# nrf5340_application register map
Vendor: Nordic Semiconductor; Series: nrf53; File version: 1
CPU: CM33 r0p4, little endian, MPU, FPU, 3 interrupt priority bits, 69 interrupts
Registers are 32-bit, read-write, reset 0x0 unless marked. A register's access mark holds for its fields unless they carry their own. Offsets are from the block's base; [hi:lo] are bit positions; lines under a group give offsets from that group; {n}, {i} and the like mark numbered series; 'fields as' and 'values as' point back to an identical list.

## USBD_NS — Universal serial bus device 0
Base 0x40036000
Same registers: USBD_S 0x50036000
{0x4+4i} TASKS_STARTEPIN[{i}] (i=0..7) wo — Description collection: Captures the EPIN[n].PTR and EPIN[n].MAXCNT registers values, and enables endpoint IN n to respond to traffic from host
  [0] TASKS_STARTEPIN — Captures the EPIN[n].PTR and EPIN[n].MAXCNT registers values, and enables endpoint IN n to respond to traffic from host
    1=Trigger task
0x24 TASKS_STARTISOIN wo — Captures the ISOIN.PTR and ISOIN.MAXCNT registers values, and enables sending data on ISO endpoint
  [0] TASKS_STARTISOIN
    1=Trigger task
{0x28+4i} TASKS_STARTEPOUT[{i}] (i=0..7) wo — Description collection: Captures the EPOUT[n].PTR and EPOUT[n].MAXCNT registers values, and enables endpoint n to respond to traffic from host
  [0] TASKS_STARTEPOUT — Captures the EPOUT[n].PTR and EPOUT[n].MAXCNT registers values, and enables endpoint n to respond to traffic from host
    1=Trigger task
0x48 TASKS_STARTISOOUT wo — Captures the ISOOUT.PTR and ISOOUT.MAXCNT registers values, and enables receiving of data on ISO endpoint
  [0] TASKS_STARTISOOUT
    1=Trigger task
0x4C TASKS_EP0RCVOUT wo — Allows OUT data stage on control endpoint 0
  [0] TASKS_EP0RCVOUT
    1=Trigger task
0x50 TASKS_EP0STATUS wo — Allows status stage on control endpoint 0
  [0] TASKS_EP0STATUS
    1=Trigger task
0x54 TASKS_EP0STALL wo — Stalls data and status stage on control endpoint 0
  [0] TASKS_EP0STALL
    1=Trigger task
0x58 TASKS_DPDMDRIVE wo — Forces D+ and D- lines into the state defined in the DPDMVALUE register
  [0] TASKS_DPDMDRIVE
    1=Trigger task
0x5C TASKS_DPDMNODRIVE wo — Stops forcing D+ and D- lines into any state (USB engine takes control)
  [0] TASKS_DPDMNODRIVE
    1=Trigger task
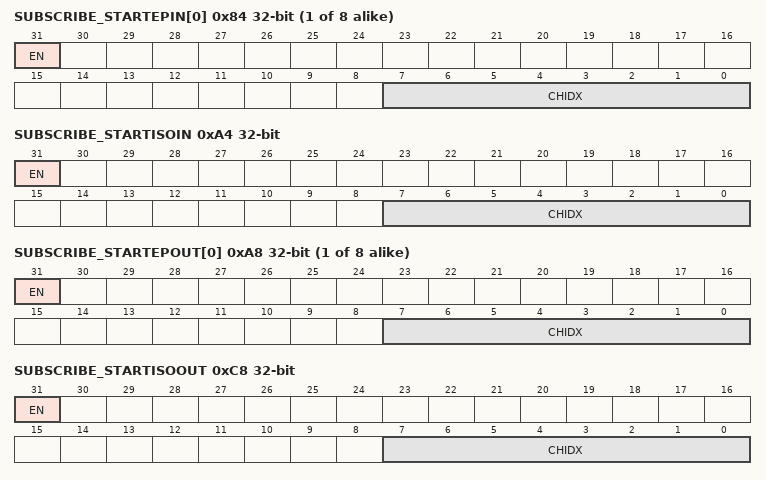
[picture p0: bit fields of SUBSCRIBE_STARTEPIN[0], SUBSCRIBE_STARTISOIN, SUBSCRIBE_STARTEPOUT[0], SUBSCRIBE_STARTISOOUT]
{0x84+4i} SUBSCRIBE_STARTEPIN[{i}] (i=0..7) — Description collection: Subscribe configuration for task STARTEPIN[n]
  [31] EN
    0=Disabled (Disable subscription); 1=Enabled (Enable subscription)
  [7:0] CHIDX — DPPI channel that task STARTEPIN[n] will subscribe to
0xA4 SUBSCRIBE_STARTISOIN — Subscribe configuration for task STARTISOIN
  [31] EN
    values as SUBSCRIBE_STARTEPIN[0].EN
  [7:0] CHIDX — DPPI channel that task STARTISOIN will subscribe to
{0xA8+4i} SUBSCRIBE_STARTEPOUT[{i}] (i=0..7) — Description collection: Subscribe configuration for task STARTEPOUT[n]
  [31] EN
    values as SUBSCRIBE_STARTEPIN[0].EN
  [7:0] CHIDX — DPPI channel that task STARTEPOUT[n] will subscribe to
0xC8 SUBSCRIBE_STARTISOOUT — Subscribe configuration for task STARTISOOUT
  [31] EN
    values as SUBSCRIBE_STARTEPIN[0].EN
  [7:0] CHIDX — DPPI channel that task STARTISOOUT will subscribe to
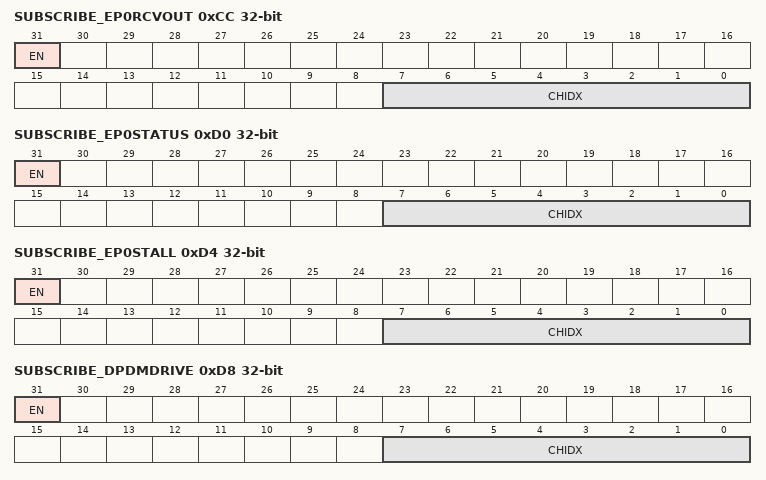
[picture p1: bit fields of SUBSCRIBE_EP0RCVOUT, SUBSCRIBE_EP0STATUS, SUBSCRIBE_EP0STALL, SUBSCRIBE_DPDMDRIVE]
0xCC SUBSCRIBE_EP0RCVOUT — Subscribe configuration for task EP0RCVOUT
  [31] EN
    values as SUBSCRIBE_STARTEPIN[0].EN
  [7:0] CHIDX — DPPI channel that task EP0RCVOUT will subscribe to
0xD0 SUBSCRIBE_EP0STATUS — Subscribe configuration for task EP0STATUS
  [31] EN
    values as SUBSCRIBE_STARTEPIN[0].EN
  [7:0] CHIDX — DPPI channel that task EP0STATUS will subscribe to
0xD4 SUBSCRIBE_EP0STALL — Subscribe configuration for task EP0STALL
  [31] EN
    values as SUBSCRIBE_STARTEPIN[0].EN
  [7:0] CHIDX — DPPI channel that task EP0STALL will subscribe to
0xD8 SUBSCRIBE_DPDMDRIVE — Subscribe configuration for task DPDMDRIVE
  [31] EN
    values as SUBSCRIBE_STARTEPIN[0].EN
  [7:0] CHIDX — DPPI channel that task DPDMDRIVE will subscribe to
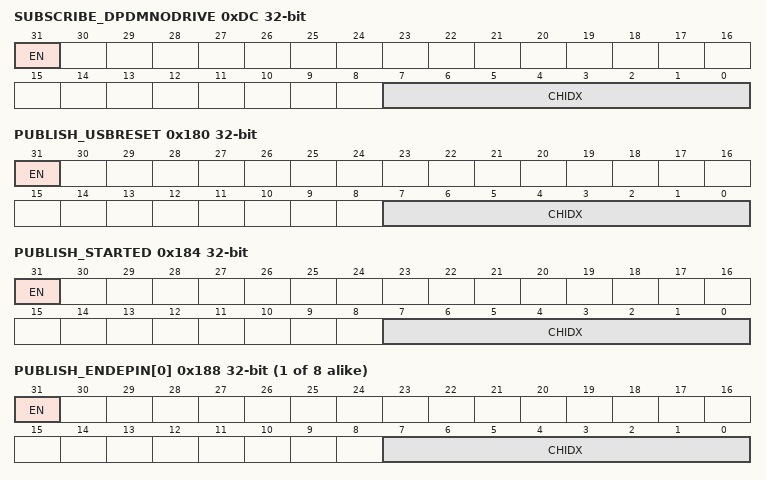
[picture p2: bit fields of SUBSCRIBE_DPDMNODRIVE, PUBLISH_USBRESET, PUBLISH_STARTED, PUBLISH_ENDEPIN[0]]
0xDC SUBSCRIBE_DPDMNODRIVE — Subscribe configuration for task DPDMNODRIVE
  [31] EN
    values as SUBSCRIBE_STARTEPIN[0].EN
  [7:0] CHIDX — DPPI channel that task DPDMNODRIVE will subscribe to
0x100 EVENTS_USBRESET — Signals that a USB reset condition has been detected on USB lines
  [0] EVENTS_USBRESET
    0=NotGenerated (Event not generated); 1=Generated (Event generated)
0x104 EVENTS_STARTED — Confirms that the EPIN[n].PTR and EPIN[n].MAXCNT, or EPOUT[n].PTR and EPOUT[n].MAXCNT registers have been captured on all endpoints reported in the EPSTATUS register
  [0] EVENTS_STARTED
    values as EVENTS_USBRESET.EVENTS_USBRESET
{0x108+4i} EVENTS_ENDEPIN[{i}] (i=0..7) — Description collection: The whole EPIN[n] buffer has been consumed. The buffer can be accessed safely by software.
  [0] EVENTS_ENDEPIN — The whole EPIN[n] buffer has been consumed. The buffer can be accessed safely by software.
    values as EVENTS_USBRESET.EVENTS_USBRESET
0x128 EVENTS_EP0DATADONE — An acknowledged data transfer has taken place on the control endpoint
  [0] EVENTS_EP0DATADONE
    values as EVENTS_USBRESET.EVENTS_USBRESET
0x12C EVENTS_ENDISOIN — The whole ISOIN buffer has been consumed. The buffer can be accessed safely by software.
  [0] EVENTS_ENDISOIN
    values as EVENTS_USBRESET.EVENTS_USBRESET
{0x130+4i} EVENTS_ENDEPOUT[{i}] (i=0..7) — Description collection: The whole EPOUT[n] buffer has been consumed. The buffer can be accessed safely by software.
  [0] EVENTS_ENDEPOUT — The whole EPOUT[n] buffer has been consumed. The buffer can be accessed safely by software.
    values as EVENTS_USBRESET.EVENTS_USBRESET
0x150 EVENTS_ENDISOOUT — The whole ISOOUT buffer has been consumed. The buffer can be accessed safely by software.
  [0] EVENTS_ENDISOOUT
    values as EVENTS_USBRESET.EVENTS_USBRESET
0x154 EVENTS_SOF — Signals that a SOF (start of frame) condition has been detected on USB lines
  [0] EVENTS_SOF
    values as EVENTS_USBRESET.EVENTS_USBRESET
0x158 EVENTS_USBEVENT — An event or an error not covered by specific events has occurred. Check EVENTCAUSE register to find the cause.
  [0] EVENTS_USBEVENT
    values as EVENTS_USBRESET.EVENTS_USBRESET
0x15C EVENTS_EP0SETUP — A valid SETUP token has been received (and acknowledged) on the control endpoint
  [0] EVENTS_EP0SETUP
    values as EVENTS_USBRESET.EVENTS_USBRESET
0x160 EVENTS_EPDATA — A data transfer has occurred on a data endpoint, indicated by the EPDATASTATUS register
  [0] EVENTS_EPDATA
    values as EVENTS_USBRESET.EVENTS_USBRESET
0x180 PUBLISH_USBRESET — Publish configuration for event USBRESET
  [31] EN
    0=Disabled (Disable publishing); 1=Enabled (Enable publishing)
  [7:0] CHIDX — DPPI channel that event USBRESET will publish to.
0x184 PUBLISH_STARTED — Publish configuration for event STARTED
  [31] EN
    values as PUBLISH_USBRESET.EN
  [7:0] CHIDX — DPPI channel that event STARTED will publish to.
{0x188+4i} PUBLISH_ENDEPIN[{i}] (i=0..7) — Description collection: Publish configuration for event ENDEPIN[n]
  [31] EN
    values as PUBLISH_USBRESET.EN
  [7:0] CHIDX — DPPI channel that event ENDEPIN[n] will publish to.
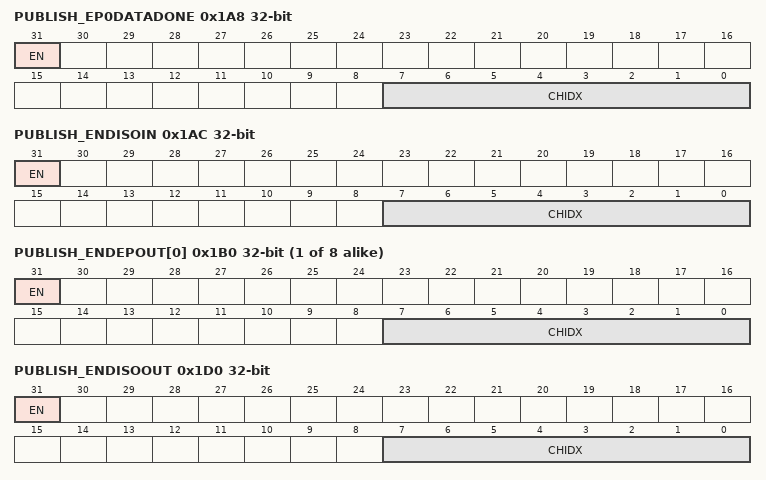
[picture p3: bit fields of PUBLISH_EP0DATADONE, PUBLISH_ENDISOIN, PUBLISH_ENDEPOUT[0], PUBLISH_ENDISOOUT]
0x1A8 PUBLISH_EP0DATADONE — Publish configuration for event EP0DATADONE
  [31] EN
    values as PUBLISH_USBRESET.EN
  [7:0] CHIDX — DPPI channel that event EP0DATADONE will publish to.
0x1AC PUBLISH_ENDISOIN — Publish configuration for event ENDISOIN
  [31] EN
    values as PUBLISH_USBRESET.EN
  [7:0] CHIDX — DPPI channel that event ENDISOIN will publish to.
{0x1B0+4i} PUBLISH_ENDEPOUT[{i}] (i=0..7) — Description collection: Publish configuration for event ENDEPOUT[n]
  [31] EN
    values as PUBLISH_USBRESET.EN
  [7:0] CHIDX — DPPI channel that event ENDEPOUT[n] will publish to.
0x1D0 PUBLISH_ENDISOOUT — Publish configuration for event ENDISOOUT
  [31] EN
    values as PUBLISH_USBRESET.EN
  [7:0] CHIDX — DPPI channel that event ENDISOOUT will publish to.
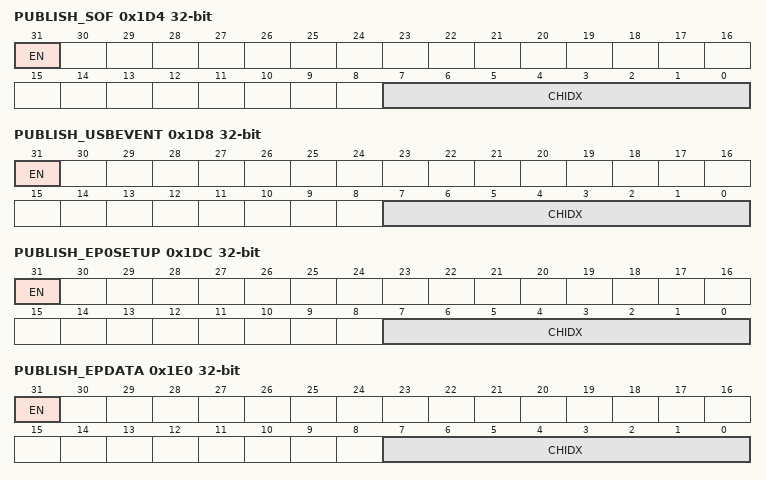
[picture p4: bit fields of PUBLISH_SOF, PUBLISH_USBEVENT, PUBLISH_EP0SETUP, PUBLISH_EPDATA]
0x1D4 PUBLISH_SOF — Publish configuration for event SOF
  [31] EN
    values as PUBLISH_USBRESET.EN
  [7:0] CHIDX — DPPI channel that event SOF will publish to.
0x1D8 PUBLISH_USBEVENT — Publish configuration for event USBEVENT
  [31] EN
    values as PUBLISH_USBRESET.EN
  [7:0] CHIDX — DPPI channel that event USBEVENT will publish to.
0x1DC PUBLISH_EP0SETUP — Publish configuration for event EP0SETUP
  [31] EN
    values as PUBLISH_USBRESET.EN
  [7:0] CHIDX — DPPI channel that event EP0SETUP will publish to.
0x1E0 PUBLISH_EPDATA — Publish configuration for event EPDATA
  [31] EN
    values as PUBLISH_USBRESET.EN
  [7:0] CHIDX — DPPI channel that event EPDATA will publish to.
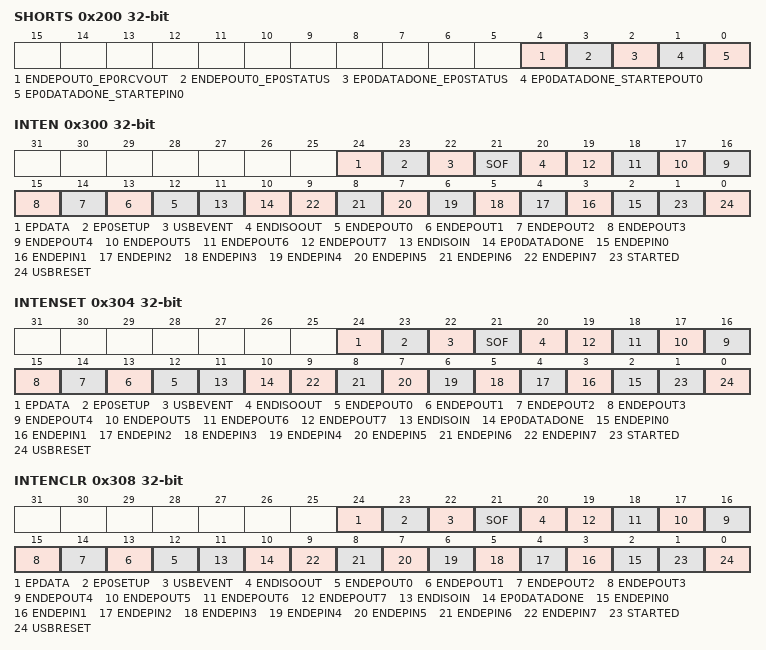
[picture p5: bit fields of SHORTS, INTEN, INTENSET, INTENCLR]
0x200 SHORTS — Shortcuts between local events and tasks
  [all] fields
    0=Disabled (Disable shortcut); 1=Enabled (Enable shortcut)
  [4] ENDEPOUT0_EP0RCVOUT — Shortcut between event ENDEPOUT[0] and task EP0RCVOUT
  [3] ENDEPOUT0_EP0STATUS — Shortcut between event ENDEPOUT[0] and task EP0STATUS
  [2] EP0DATADONE_EP0STATUS — Shortcut between event EP0DATADONE and task EP0STATUS
  [1] EP0DATADONE_STARTEPOUT0 — Shortcut between event EP0DATADONE and task STARTEPOUT[0]
  [0] EP0DATADONE_STARTEPIN0 — Shortcut between event EP0DATADONE and task STARTEPIN[0]
0x300 INTEN — Enable or disable interrupt
  [all] fields
    0=Disabled; 1=Enabled
  [24] EPDATA — Enable or disable interrupt for event EPDATA
  [23] EP0SETUP — Enable or disable interrupt for event EP0SETUP
  [22] USBEVENT — Enable or disable interrupt for event USBEVENT
  [21] SOF — Enable or disable interrupt for event SOF
  [20] ENDISOOUT — Enable or disable interrupt for event ENDISOOUT
  [n+12] ENDEPOUT{n} (n=0..7) — Enable or disable interrupt for event ENDEPOUT[{n}]
  [11] ENDISOIN — Enable or disable interrupt for event ENDISOIN
  [10] EP0DATADONE — Enable or disable interrupt for event EP0DATADONE
  [n+2] ENDEPIN{n} (n=0..7) — Enable or disable interrupt for event ENDEPIN[{n}]
  [1] STARTED — Enable or disable interrupt for event STARTED
  [0] USBRESET — Enable or disable interrupt for event USBRESET
0x304 INTENSET — Enable interrupt
  [all] fields
    on read: 0=Disabled (Read: Disabled); 1=Enabled (Read: Enabled) | on write: 1=Set (Enable)
  [24] EPDATA — Write '1' to enable interrupt for event EPDATA
  [23] EP0SETUP — Write '1' to enable interrupt for event EP0SETUP
  [22] USBEVENT — Write '1' to enable interrupt for event USBEVENT
  [21] SOF — Write '1' to enable interrupt for event SOF
  [20] ENDISOOUT — Write '1' to enable interrupt for event ENDISOOUT
  [n+12] ENDEPOUT{n} (n=0..7) — Write '1' to enable interrupt for event ENDEPOUT[{n}]
  [11] ENDISOIN — Write '1' to enable interrupt for event ENDISOIN
  [10] EP0DATADONE — Write '1' to enable interrupt for event EP0DATADONE
  [n+2] ENDEPIN{n} (n=0..7) — Write '1' to enable interrupt for event ENDEPIN[{n}]
  [1] STARTED — Write '1' to enable interrupt for event STARTED
  [0] USBRESET — Write '1' to enable interrupt for event USBRESET
0x308 INTENCLR — Disable interrupt
  [all] fields
    on read: 0=Disabled (Read: Disabled); 1=Enabled (Read: Enabled) | on write: 1=Clear (Disable)
  [24] EPDATA — Write '1' to disable interrupt for event EPDATA
  [23] EP0SETUP — Write '1' to disable interrupt for event EP0SETUP
  [22] USBEVENT — Write '1' to disable interrupt for event USBEVENT
  [21] SOF — Write '1' to disable interrupt for event SOF
  [20] ENDISOOUT — Write '1' to disable interrupt for event ENDISOOUT
  [n+12] ENDEPOUT{n} (n=0..7) — Write '1' to disable interrupt for event ENDEPOUT[{n}]
  [11] ENDISOIN — Write '1' to disable interrupt for event ENDISOIN
  [10] EP0DATADONE — Write '1' to disable interrupt for event EP0DATADONE
  [n+2] ENDEPIN{n} (n=0..7) — Write '1' to disable interrupt for event ENDEPIN[{n}]
  [1] STARTED — Write '1' to disable interrupt for event STARTED
  [0] USBRESET — Write '1' to disable interrupt for event USBRESET
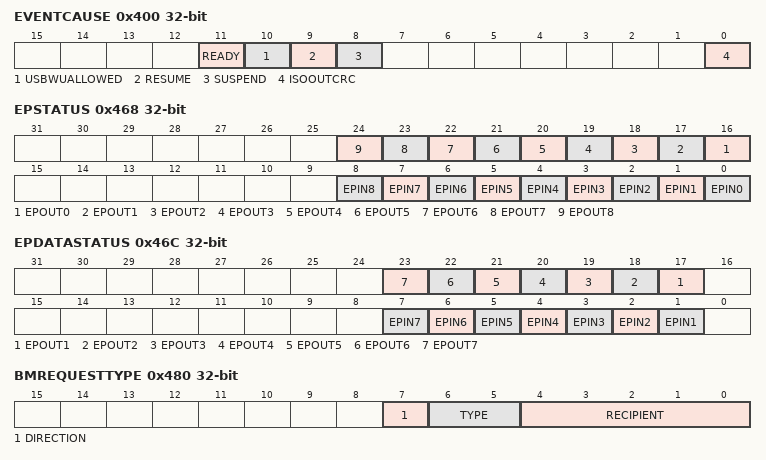
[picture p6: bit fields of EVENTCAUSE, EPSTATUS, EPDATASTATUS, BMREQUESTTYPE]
0x400 EVENTCAUSE write-1-clears — Details on what caused the USBEVENT event
  [11] READY — USB device is ready for normal operation. Write '1' to clear.
    0=NotDetected (USBEVENT was not issued due to USBD peripheral ready); 1=Ready (USBD peripheral is ready)
  [10] USBWUALLOWED — USB MAC has been woken up and operational. Write '1' to clear.
    0=NotAllowed (Wake up not allowed); 1=Allowed (Wake up allowed)
  [9] RESUME — Signals that a RESUME condition (K state or activity restart) has been detected on USB lines. Write '1' to clear.
    0=NotDetected (Resume not detected); 1=Detected (Resume detected)
  [8] SUSPEND — Signals that USB lines have been idle long enough for the device to enter suspend. Write '1' to clear.
    0=NotDetected (Suspend not detected); 1=Detected (Suspend detected)
  [0] ISOOUTCRC — CRC error was detected on isochronous OUT endpoint 8. Write '1' to clear.
    0=NotDetected (No error detected); 1=Detected (Error detected)
0x420 HALTED group — Unspecified
  {0x0+4j} EPIN[{j}] (j=0..7) ro — Description collection: IN endpoint halted status. Can be used as is as response to a GetStatus() request to endpoint.
    [15:0] GETSTATUS — IN endpoint halted status. Can be used as is as response to a GetStatus() request to endpoint.
      0=NotHalted (Endpoint is not halted); 1=Halted (Endpoint is halted)
  {0x24+4j} EPOUT[{j}] (j=0..7) ro — Description collection: OUT endpoint halted status. Can be used as is as response to a GetStatus() request to endpoint.
    [15:0] GETSTATUS — OUT endpoint halted status. Can be used as is as response to a GetStatus() request to endpoint.
      values as HALTED.EPIN[0].GETSTATUS
0x468 EPSTATUS write-1-clears — Provides information on which endpoint's EasyDMA registers have been captured
  [all] fields
    0=NoData (EasyDMA registers have not been captured for this endpoint); 1=DataDone (EasyDMA registers have been captured for this endpoint)
  [n+16] EPOUT{n} (n=0..8) — Captured state of endpoint's EasyDMA registers. Write '1' to clear.
  [n] EPIN{n} (n=0..8) — Captured state of endpoint's EasyDMA registers. Write '1' to clear.
0x46C EPDATASTATUS write-1-clears — Provides information on which endpoint(s) an acknowledged data transfer has occurred (EPDATA event)
  [n+16] EPOUT{n} (n=1..7) — Acknowledged data transfer on this OUT endpoint. Write '1' to clear.
    0=NotStarted (No acknowledged data transfer on this endpoint); 1=Started (Acknowledged data transfer on this endpoint has occurred)
  [n] EPIN{n} (n=1..7) — Acknowledged data transfer on this IN endpoint. Write '1' to clear.
    0=NotDone (No acknowledged data transfer on this endpoint); 1=DataDone (Acknowledged data transfer on this endpoint has occurred)
0x470 USBADDR ro — Device USB address
  [6:0] ADDR
0x480 BMREQUESTTYPE ro — SETUP data, byte 0, bmRequestType
  [7] DIRECTION — Data transfer direction
    0=HostToDevice; 1=DeviceToHost
  [6:5] TYPE — Data transfer type
    0=Standard; 1=Class; 2=Vendor
  [4:0] RECIPIENT — Data transfer type
    0=Device; 1=Interface; 2=Endpoint; 3=Other
0x484 BREQUEST ro — SETUP data, byte 1, bRequest
  [7:0] BREQUEST — SETUP data, byte 1, bRequest. Values provided for standard requests only, user must implement class and vendor values.
    0=STD_GET_STATUS (Standard request GET_STATUS); 1=STD_CLEAR_FEATURE (Standard request CLEAR_FEATURE); 3=STD_SET_FEATURE (Standard request SET_FEATURE); 5=STD_SET_ADDRESS (Standard request SET_ADDRESS); 6=STD_GET_DESCRIPTOR (Standard request GET_DESCRIPTOR); 7=STD_SET_DESCRIPTOR (Standard request SET_DESCRIPTOR); 8=STD_GET_CONFIGURATION (Standard request GET_CONFIGURATION); 9=STD_SET_CONFIGURATION (Standard request SET_CONFIGURATION); 10=STD_GET_INTERFACE (Standard request GET_INTERFACE); 11=STD_SET_INTERFACE (Standard request SET_INTERFACE); 12=STD_SYNCH_FRAME (Standard request SYNCH_FRAME)
0x488 WVALUEL ro — SETUP data, byte 2, LSB of wValue
  [7:0] WVALUEL
0x48C WVALUEH ro — SETUP data, byte 3, MSB of wValue
  [7:0] WVALUEH
0x490 WINDEXL ro — SETUP data, byte 4, LSB of wIndex
  [7:0] WINDEXL
0x494 WINDEXH ro — SETUP data, byte 5, MSB of wIndex
  [7:0] WINDEXH
0x498 WLENGTHL ro — SETUP data, byte 6, LSB of wLength
  [7:0] WLENGTHL
0x49C WLENGTHH ro — SETUP data, byte 7, MSB of wLength
  [7:0] WLENGTHH
0x4A0 SIZE group — Unspecified
  {0x0+4j} EPOUT[{j}] (j=0..7) write-0-clears — Description collection: Number of bytes received last in the data stage of this OUT endpoint
    [6:0] SIZE — Number of bytes received last in the data stage of this OUT endpoint
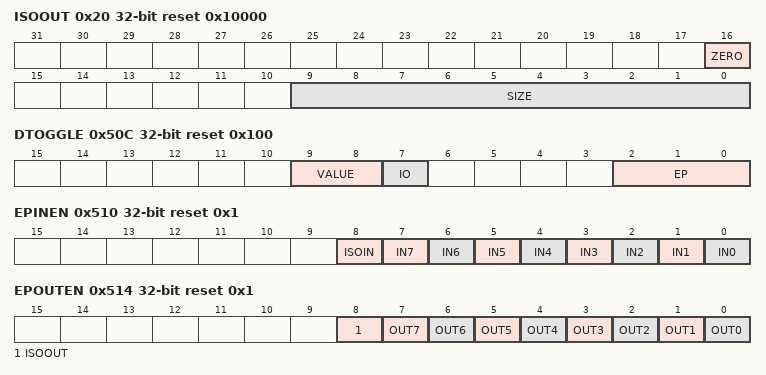
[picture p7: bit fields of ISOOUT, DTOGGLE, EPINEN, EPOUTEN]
  0x20 ISOOUT ro reset 0x10000 — Number of bytes received last on this ISO OUT data endpoint
    [16] ZERO — Zero-length data packet received
      0=Normal (No zero-length data received, use value in SIZE); 1=ZeroData (Zero-length data received, ignore value in SIZE)
    [9:0] SIZE — Number of bytes received last on this ISO OUT data endpoint
0x500 ENABLE — Enable USB
  [0] ENABLE
    0=Disabled (USB peripheral is disabled); 1=Enabled (USB peripheral is enabled)
0x504 USBPULLUP — Control of the USB pull-up
  [0] CONNECT — Control of the USB pull-up on the D+ line
    0=Disabled (Pull-up is disconnected); 1=Enabled (Pull-up is connected to D+)
0x508 DPDMVALUE — State D+ and D- lines will be forced into by the DPDMDRIVE task. The DPDMNODRIVE task reverts the control of the lines to MAC IP (no forcing).
  [4:0] STATE — State D+ and D- lines will be forced into by the DPDMDRIVE task
    1=Resume (D+ forced low, D- forced high (K state) for a timing preset in hardware (50 us or 5 ms, depending on bus state)); 2=J (D+ forced high, D- forced low (J state)); 4=K (D+ forced low, D- forced high (K state))
0x50C DTOGGLE reset 0x100 — Data toggle control and status
  [9:8] VALUE — Data toggle value
    0=Nop (No action on data toggle when writing the register with this value); 1=Data0 (Data toggle is DATA0 on endpoint set by EP and IO); 2=Data1 (Data toggle is DATA1 on endpoint set by EP and IO)
  [7] IO — Selects IN or OUT endpoint
    0=Out (Selects OUT endpoint); 1=In (Selects IN endpoint)
  [2:0] EP — Select bulk endpoint number
0x510 EPINEN reset 0x1 — Endpoint IN enable
  [8] ISOIN — Enable ISO IN endpoint
    0=Disable ISO IN endpoint 8; 1=Enable ISO IN endpoint 8
  [n] IN{n} (n=0..7) — Enable IN endpoint {n}
    0=Disable endpoint IN {n} (no response to IN tokens); 1=Enable endpoint IN {n} (response to IN tokens)
0x514 EPOUTEN reset 0x1 — Endpoint OUT enable
  [8] ISOOUT — Enable ISO OUT endpoint 8
    0=Disable ISO OUT endpoint 8; 1=Enable ISO OUT endpoint 8
  [n] OUT{n} (n=0..7) — Enable OUT endpoint {n}
    0=Disable endpoint OUT {n} (no response to OUT tokens); 1=Enable endpoint OUT {n} (response to OUT tokens)
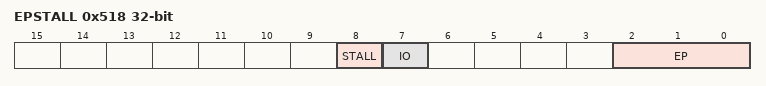
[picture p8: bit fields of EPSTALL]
0x518 EPSTALL wo read-has-side-effects — STALL endpoints
  [8] STALL — Stall selected endpoint
    0=UnStall (Don't stall selected endpoint); 1=Stall selected endpoint
  [7] IO — Selects IN or OUT endpoint
    0=Out (Selects OUT endpoint); 1=In (Selects IN endpoint)
  [2:0] EP — Select endpoint number
0x51C ISOSPLIT — Controls the split of ISO buffers
  [15:0] SPLIT
    0=OneDir (Full buffer dedicated to either iso IN or OUT); 128=HalfIN (Lower half for IN, upper half for OUT)
0x520 FRAMECNTR ro — Returns the current value of the start of frame counter
  [10:0] FRAMECNTR
0x52C LOWPOWER — Controls USBD peripheral low power mode during USB suspend
  [0] LOWPOWER — Controls USBD peripheral low-power mode during USB suspend
    0=ForceNormal (Software must write this value to exit low power mode and before performing a remote wake-up); 1=LowPower (Software must write this value to enter low power mode after DMA and software have finished interacting with the USB peripheral)
0x530 ISOINCONFIG — Controls the response of the ISO IN endpoint to an IN token when no data is ready to be sent
  [0] RESPONSE
    0=NoResp (Endpoint does not respond in that case); 1=ZeroData (Endpoint responds with a zero-length data packet in that case)
{0x600+0x14*i} EPIN[{i}] (i=0..7) group — Unspecified
  0x00 PTR — Description cluster: Data pointer
    [31:0] PTR — Data pointer
  0x04 MAXCNT — Description cluster: Maximum number of bytes to transfer
    [6:0] MAXCNT — Maximum number of bytes to transfer
  0x08 AMOUNT ro — Description cluster: Number of bytes transferred in the last transaction
    [6:0] AMOUNT — Number of bytes transferred in the last transaction
0x6A0 ISOIN group — Unspecified
  0x00 PTR — Data pointer
  0x04 MAXCNT — Maximum number of bytes to transfer
    [9:0] MAXCNT
  0x08 AMOUNT ro — Number of bytes transferred in the last transaction
    [9:0] AMOUNT
{0x700+0x14*i} EPOUT[{i}] (i=0..7) group — Unspecified
  0x00 PTR — Description cluster: Data pointer
    [31:0] PTR — Data pointer
  0x04 MAXCNT — Description cluster: Maximum number of bytes to transfer
    [6:0] MAXCNT — Maximum number of bytes to transfer
  0x08 AMOUNT ro — Description cluster: Number of bytes transferred in the last transaction
    [6:0] AMOUNT — Number of bytes transferred in the last transaction
0x7A0 ISOOUT group — Unspecified
  0x00 PTR — Data pointer
  0x04 MAXCNT — Maximum number of bytes to transfer
    [9:0] MAXCNT
  0x08 AMOUNT ro — Number of bytes transferred in the last transaction
    [9:0] AMOUNT
